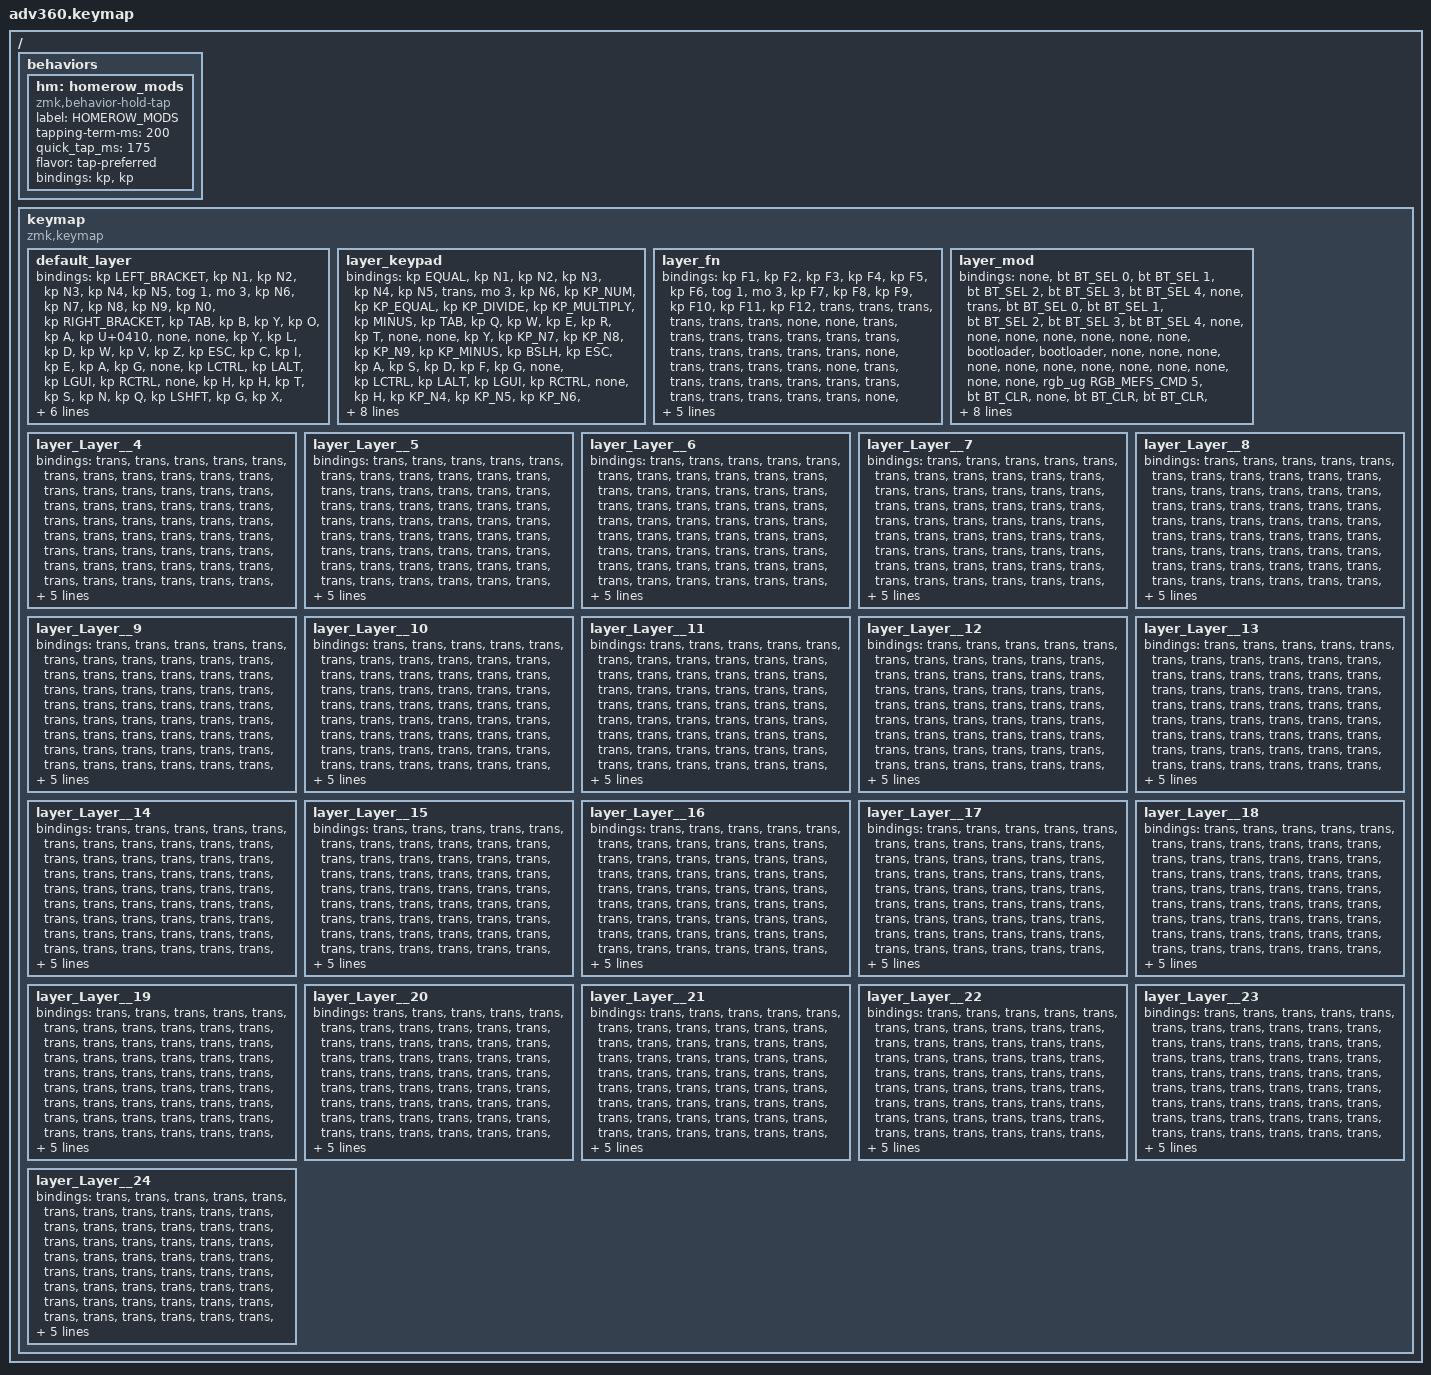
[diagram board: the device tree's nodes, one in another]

/*
 * Copyright (c) 2020 The ZMK Contributors
 *
 * SPDX-License-Identifier: MIT
 */


/* THIS FILE WAS GENERATED!
 *
 * This file was generated automatically. You may or may not want to
 * edit it directly.
 */

#include <behaviors.dtsi>
#include <dt-bindings/zmk/keys.h>
#include <dt-bindings/zmk/bt.h>
#include <dt-bindings/zmk/rgb.h>
#include <dt-bindings/zmk/backlight.h>

/ {
  behaviors {
    #include "macros.dtsi"
    #include "version.dtsi"

    hm: homerow_mods {
        compatible = "zmk,behavior-hold-tap";
        label = "HOMEROW_MODS";
        #binding-cells = <2>;
        tapping-term-ms = <200>;
        quick_tap_ms = <175>;
        flavor = "tap-preferred";
        bindings = <&kp>, <&kp>;
    };
  };

    keymap {
        compatible = "zmk,keymap";


        default_layer {
            bindings = <
 &kp LEFT_BRACKET     &kp N1    &kp N2    &kp N3     &kp N4      &kp N5             &tog 1      &mo 3     &kp N6     &kp N7     &kp N8     &kp N9     &kp N0  &kp RIGHT_BRACKET
          &kp TAB      &kp B     &kp Y     &kp O      &kp A  &kp U+0410              &none      &none      &kp Y      &kp L      &kp D      &kp W      &kp V              &kp Z
          &kp ESC      &kp C     &kp I     &kp E      &kp A       &kp G              &none  &kp LCTRL   &kp LALT                         &kp LGUI  &kp RCTRL              &none        &kp H   &kp H   &kp T   &kp S   &kp N      &kp Q
        &kp LSHFT      &kp G     &kp X     &kp J      &kp K       &kp B              &none      &none   &kp HOME      &none      &none  &kp PG_UP      &none              &none        &kp N   &kp R   &kp M   &kp F   &kp P  &kp RSHFT
            &mo 2  &kp GRAVE  &kp CAPS  &kp LEFT  &kp RIGHT    &kp BSPC            &kp DEL    &kp END  &kp PG_DN  &kp ENTER  &kp SPACE     &kp UP   &kp DOWN           &kp HASH  &kp AT_SIGN   &mo 2
            >;
        };

        layer_keypad {
            bindings = <
 &kp EQUAL     &kp N1    &kp N2    &kp N3     &kp N4    &kp N5             &trans      &mo 3     &kp N6  &kp KP_NUM  &kp KP_EQUAL  &kp KP_DIVIDE  &kp KP_MULTIPLY   &kp MINUS
   &kp TAB      &kp Q     &kp W     &kp E      &kp R     &kp T              &none      &none      &kp Y   &kp KP_N7     &kp KP_N8      &kp KP_N9     &kp KP_MINUS    &kp BSLH
   &kp ESC      &kp A     &kp S     &kp D      &kp F     &kp G              &none  &kp LCTRL   &kp LALT                                 &kp LGUI        &kp RCTRL       &none     &kp H  &kp KP_N4  &kp KP_N5  &kp KP_N6   &kp KP_PLUS    &kp SQT
 &kp LSHFT      &kp Z     &kp X     &kp C      &kp V     &kp B              &none      &none   &kp HOME       &none         &none      &kp PG_UP            &none       &none     &kp N  &kp KP_N1  &kp KP_N2  &kp KP_N3  &kp KP_ENTER  &kp RSHFT
     &mo 2  &kp GRAVE  &kp CAPS  &kp LEFT  &kp RIGHT  &kp BSPC            &kp DEL    &kp END  &kp PG_DN   &kp ENTER     &kp KP_N0         &kp UP         &kp DOWN  &kp KP_DOT  &kp RBKT      &mo 2
            >;
        };

        layer_fn {
            bindings = <
 &kp F1  &kp F2  &kp F3  &kp F4  &kp F5  &kp F6            &tog 1   &mo 3  &kp F7  &kp F8  &kp F9  &kp F10  &kp F11  &kp F12
 &trans  &trans  &trans  &trans  &trans  &trans             &none   &none  &trans  &trans  &trans   &trans   &trans   &trans
 &trans  &trans  &trans  &trans  &trans  &trans             &none  &trans  &trans                   &trans   &trans    &none  &trans  &trans  &trans  &trans  &trans  &trans
 &trans  &trans  &trans  &trans  &trans  &trans             &none   &none  &trans   &none   &none   &trans    &none    &none  &trans  &trans  &trans  &trans  &trans  &trans
 &trans  &trans  &trans  &trans  &trans  &trans            &trans  &trans  &trans  &trans  &trans   &trans   &trans   &trans  &trans  &trans
            >;
        };

        layer_mod {
            bindings = <
  &none  &bt BT_SEL 0  &bt BT_SEL 1  &bt BT_SEL 2  &bt BT_SEL 3     &bt BT_SEL 4                             &none       &trans  &bt BT_SEL 0  &bt BT_SEL 1     &bt BT_SEL 2  &bt BT_SEL 3  &bt BT_SEL 4                   &none
  &none         &none         &none         &none         &none            &none                       &bootloader  &bootloader         &none         &none            &none         &none         &none                   &none
  &none         &none         &none         &none         &none            &none            &rgb_ug RGB_MEFS_CMD 5   &bt BT_CLR         &none                                   &bt BT_CLR    &bt BT_CLR  &rgb_ug RGB_MEFS_CMD 5   &none   &none   &none   &none   &none   &none
  &none         &none         &none         &none         &none            &none                             &none        &none         &none         &none            &none         &none         &none                   &none   &none   &none   &none   &none   &none   &none
  &none         &none         &none    &bl BL_INC    &bl BL_DEC  &rgb_ug RGB_TOG                        &bl BL_TOG        &none         &none    &bl BL_TOG  &rgb_ug RGB_TOG    &bl BL_INC    &bl BL_DEC                   &none   &none   &none
            >;
        };

        layer_Layer__4 {
            bindings = <
 &trans  &trans  &trans  &trans  &trans  &trans            &trans  &trans  &trans  &trans  &trans  &trans  &trans  &trans
 &trans  &trans  &trans  &trans  &trans  &trans            &trans  &trans  &trans  &trans  &trans  &trans  &trans  &trans
 &trans  &trans  &trans  &trans  &trans  &trans            &trans  &trans  &trans                  &trans  &trans  &trans  &trans  &trans  &trans  &trans  &trans  &trans
 &trans  &trans  &trans  &trans  &trans  &trans            &trans  &trans  &trans  &trans  &trans  &trans  &trans  &trans  &trans  &trans  &trans  &trans  &trans  &trans
 &trans  &trans  &trans  &trans  &trans  &trans            &trans  &trans  &trans  &trans  &trans  &trans  &trans  &trans  &trans  &trans
            >;
        };

        layer_Layer__5 {
            bindings = <
 &trans  &trans  &trans  &trans  &trans  &trans            &trans  &trans  &trans  &trans  &trans  &trans  &trans  &trans
 &trans  &trans  &trans  &trans  &trans  &trans            &trans  &trans  &trans  &trans  &trans  &trans  &trans  &trans
 &trans  &trans  &trans  &trans  &trans  &trans            &trans  &trans  &trans                  &trans  &trans  &trans  &trans  &trans  &trans  &trans  &trans  &trans
 &trans  &trans  &trans  &trans  &trans  &trans            &trans  &trans  &trans  &trans  &trans  &trans  &trans  &trans  &trans  &trans  &trans  &trans  &trans  &trans
 &trans  &trans  &trans  &trans  &trans  &trans            &trans  &trans  &trans  &trans  &trans  &trans  &trans  &trans  &trans  &trans
            >;
        };

        layer_Layer__6 {
            bindings = <
 &trans  &trans  &trans  &trans  &trans  &trans            &trans  &trans  &trans  &trans  &trans  &trans  &trans  &trans
 &trans  &trans  &trans  &trans  &trans  &trans            &trans  &trans  &trans  &trans  &trans  &trans  &trans  &trans
 &trans  &trans  &trans  &trans  &trans  &trans            &trans  &trans  &trans                  &trans  &trans  &trans  &trans  &trans  &trans  &trans  &trans  &trans
 &trans  &trans  &trans  &trans  &trans  &trans            &trans  &trans  &trans  &trans  &trans  &trans  &trans  &trans  &trans  &trans  &trans  &trans  &trans  &trans
 &trans  &trans  &trans  &trans  &trans  &trans            &trans  &trans  &trans  &trans  &trans  &trans  &trans  &trans  &trans  &trans
            >;
        };

        layer_Layer__7 {
            bindings = <
 &trans  &trans  &trans  &trans  &trans  &trans            &trans  &trans  &trans  &trans  &trans  &trans  &trans  &trans
 &trans  &trans  &trans  &trans  &trans  &trans            &trans  &trans  &trans  &trans  &trans  &trans  &trans  &trans
 &trans  &trans  &trans  &trans  &trans  &trans            &trans  &trans  &trans                  &trans  &trans  &trans  &trans  &trans  &trans  &trans  &trans  &trans
 &trans  &trans  &trans  &trans  &trans  &trans            &trans  &trans  &trans  &trans  &trans  &trans  &trans  &trans  &trans  &trans  &trans  &trans  &trans  &trans
 &trans  &trans  &trans  &trans  &trans  &trans            &trans  &trans  &trans  &trans  &trans  &trans  &trans  &trans  &trans  &trans
            >;
        };

        layer_Layer__8 {
            bindings = <
 &trans  &trans  &trans  &trans  &trans  &trans            &trans  &trans  &trans  &trans  &trans  &trans  &trans  &trans
 &trans  &trans  &trans  &trans  &trans  &trans            &trans  &trans  &trans  &trans  &trans  &trans  &trans  &trans
 &trans  &trans  &trans  &trans  &trans  &trans            &trans  &trans  &trans                  &trans  &trans  &trans  &trans  &trans  &trans  &trans  &trans  &trans
 &trans  &trans  &trans  &trans  &trans  &trans            &trans  &trans  &trans  &trans  &trans  &trans  &trans  &trans  &trans  &trans  &trans  &trans  &trans  &trans
 &trans  &trans  &trans  &trans  &trans  &trans            &trans  &trans  &trans  &trans  &trans  &trans  &trans  &trans  &trans  &trans
            >;
        };

        layer_Layer__9 {
            bindings = <
 &trans  &trans  &trans  &trans  &trans  &trans            &trans  &trans  &trans  &trans  &trans  &trans  &trans  &trans
 &trans  &trans  &trans  &trans  &trans  &trans            &trans  &trans  &trans  &trans  &trans  &trans  &trans  &trans
 &trans  &trans  &trans  &trans  &trans  &trans            &trans  &trans  &trans                  &trans  &trans  &trans  &trans  &trans  &trans  &trans  &trans  &trans
 &trans  &trans  &trans  &trans  &trans  &trans            &trans  &trans  &trans  &trans  &trans  &trans  &trans  &trans  &trans  &trans  &trans  &trans  &trans  &trans
 &trans  &trans  &trans  &trans  &trans  &trans            &trans  &trans  &trans  &trans  &trans  &trans  &trans  &trans  &trans  &trans
            >;
        };

        layer_Layer__10 {
            bindings = <
 &trans  &trans  &trans  &trans  &trans  &trans            &trans  &trans  &trans  &trans  &trans  &trans  &trans  &trans
 &trans  &trans  &trans  &trans  &trans  &trans            &trans  &trans  &trans  &trans  &trans  &trans  &trans  &trans
 &trans  &trans  &trans  &trans  &trans  &trans            &trans  &trans  &trans                  &trans  &trans  &trans  &trans  &trans  &trans  &trans  &trans  &trans
 &trans  &trans  &trans  &trans  &trans  &trans            &trans  &trans  &trans  &trans  &trans  &trans  &trans  &trans  &trans  &trans  &trans  &trans  &trans  &trans
 &trans  &trans  &trans  &trans  &trans  &trans            &trans  &trans  &trans  &trans  &trans  &trans  &trans  &trans  &trans  &trans
            >;
        };

        layer_Layer__11 {
            bindings = <
 &trans  &trans  &trans  &trans  &trans  &trans            &trans  &trans  &trans  &trans  &trans  &trans  &trans  &trans
 &trans  &trans  &trans  &trans  &trans  &trans            &trans  &trans  &trans  &trans  &trans  &trans  &trans  &trans
 &trans  &trans  &trans  &trans  &trans  &trans            &trans  &trans  &trans                  &trans  &trans  &trans  &trans  &trans  &trans  &trans  &trans  &trans
 &trans  &trans  &trans  &trans  &trans  &trans            &trans  &trans  &trans  &trans  &trans  &trans  &trans  &trans  &trans  &trans  &trans  &trans  &trans  &trans
 &trans  &trans  &trans  &trans  &trans  &trans            &trans  &trans  &trans  &trans  &trans  &trans  &trans  &trans  &trans  &trans
            >;
        };

        layer_Layer__12 {
            bindings = <
 &trans  &trans  &trans  &trans  &trans  &trans            &trans  &trans  &trans  &trans  &trans  &trans  &trans  &trans
 &trans  &trans  &trans  &trans  &trans  &trans            &trans  &trans  &trans  &trans  &trans  &trans  &trans  &trans
 &trans  &trans  &trans  &trans  &trans  &trans            &trans  &trans  &trans                  &trans  &trans  &trans  &trans  &trans  &trans  &trans  &trans  &trans
 &trans  &trans  &trans  &trans  &trans  &trans            &trans  &trans  &trans  &trans  &trans  &trans  &trans  &trans  &trans  &trans  &trans  &trans  &trans  &trans
 &trans  &trans  &trans  &trans  &trans  &trans            &trans  &trans  &trans  &trans  &trans  &trans  &trans  &trans  &trans  &trans
            >;
        };

        layer_Layer__13 {
            bindings = <
 &trans  &trans  &trans  &trans  &trans  &trans            &trans  &trans  &trans  &trans  &trans  &trans  &trans  &trans
 &trans  &trans  &trans  &trans  &trans  &trans            &trans  &trans  &trans  &trans  &trans  &trans  &trans  &trans
 &trans  &trans  &trans  &trans  &trans  &trans            &trans  &trans  &trans                  &trans  &trans  &trans  &trans  &trans  &trans  &trans  &trans  &trans
 &trans  &trans  &trans  &trans  &trans  &trans            &trans  &trans  &trans  &trans  &trans  &trans  &trans  &trans  &trans  &trans  &trans  &trans  &trans  &trans
 &trans  &trans  &trans  &trans  &trans  &trans            &trans  &trans  &trans  &trans  &trans  &trans  &trans  &trans  &trans  &trans
            >;
        };

        layer_Layer__14 {
            bindings = <
 &trans  &trans  &trans  &trans  &trans  &trans            &trans  &trans  &trans  &trans  &trans  &trans  &trans  &trans
 &trans  &trans  &trans  &trans  &trans  &trans            &trans  &trans  &trans  &trans  &trans  &trans  &trans  &trans
 &trans  &trans  &trans  &trans  &trans  &trans            &trans  &trans  &trans                  &trans  &trans  &trans  &trans  &trans  &trans  &trans  &trans  &trans
 &trans  &trans  &trans  &trans  &trans  &trans            &trans  &trans  &trans  &trans  &trans  &trans  &trans  &trans  &trans  &trans  &trans  &trans  &trans  &trans
 &trans  &trans  &trans  &trans  &trans  &trans            &trans  &trans  &trans  &trans  &trans  &trans  &trans  &trans  &trans  &trans
            >;
        };

        layer_Layer__15 {
            bindings = <
 &trans  &trans  &trans  &trans  &trans  &trans            &trans  &trans  &trans  &trans  &trans  &trans  &trans  &trans
 &trans  &trans  &trans  &trans  &trans  &trans            &trans  &trans  &trans  &trans  &trans  &trans  &trans  &trans
 &trans  &trans  &trans  &trans  &trans  &trans            &trans  &trans  &trans                  &trans  &trans  &trans  &trans  &trans  &trans  &trans  &trans  &trans
 &trans  &trans  &trans  &trans  &trans  &trans            &trans  &trans  &trans  &trans  &trans  &trans  &trans  &trans  &trans  &trans  &trans  &trans  &trans  &trans
 &trans  &trans  &trans  &trans  &trans  &trans            &trans  &trans  &trans  &trans  &trans  &trans  &trans  &trans  &trans  &trans
            >;
        };

        layer_Layer__16 {
            bindings = <
 &trans  &trans  &trans  &trans  &trans  &trans            &trans  &trans  &trans  &trans  &trans  &trans  &trans  &trans
 &trans  &trans  &trans  &trans  &trans  &trans            &trans  &trans  &trans  &trans  &trans  &trans  &trans  &trans
 &trans  &trans  &trans  &trans  &trans  &trans            &trans  &trans  &trans                  &trans  &trans  &trans  &trans  &trans  &trans  &trans  &trans  &trans
 &trans  &trans  &trans  &trans  &trans  &trans            &trans  &trans  &trans  &trans  &trans  &trans  &trans  &trans  &trans  &trans  &trans  &trans  &trans  &trans
 &trans  &trans  &trans  &trans  &trans  &trans            &trans  &trans  &trans  &trans  &trans  &trans  &trans  &trans  &trans  &trans
            >;
        };

        layer_Layer__17 {
            bindings = <
 &trans  &trans  &trans  &trans  &trans  &trans            &trans  &trans  &trans  &trans  &trans  &trans  &trans  &trans
 &trans  &trans  &trans  &trans  &trans  &trans            &trans  &trans  &trans  &trans  &trans  &trans  &trans  &trans
 &trans  &trans  &trans  &trans  &trans  &trans            &trans  &trans  &trans                  &trans  &trans  &trans  &trans  &trans  &trans  &trans  &trans  &trans
 &trans  &trans  &trans  &trans  &trans  &trans            &trans  &trans  &trans  &trans  &trans  &trans  &trans  &trans  &trans  &trans  &trans  &trans  &trans  &trans
 &trans  &trans  &trans  &trans  &trans  &trans            &trans  &trans  &trans  &trans  &trans  &trans  &trans  &trans  &trans  &trans
            >;
        };

        layer_Layer__18 {
            bindings = <
 &trans  &trans  &trans  &trans  &trans  &trans            &trans  &trans  &trans  &trans  &trans  &trans  &trans  &trans
 &trans  &trans  &trans  &trans  &trans  &trans            &trans  &trans  &trans  &trans  &trans  &trans  &trans  &trans
 &trans  &trans  &trans  &trans  &trans  &trans            &trans  &trans  &trans                  &trans  &trans  &trans  &trans  &trans  &trans  &trans  &trans  &trans
 &trans  &trans  &trans  &trans  &trans  &trans            &trans  &trans  &trans  &trans  &trans  &trans  &trans  &trans  &trans  &trans  &trans  &trans  &trans  &trans
 &trans  &trans  &trans  &trans  &trans  &trans            &trans  &trans  &trans  &trans  &trans  &trans  &trans  &trans  &trans  &trans
            >;
        };

        layer_Layer__19 {
            bindings = <
 &trans  &trans  &trans  &trans  &trans  &trans            &trans  &trans  &trans  &trans  &trans  &trans  &trans  &trans
 &trans  &trans  &trans  &trans  &trans  &trans            &trans  &trans  &trans  &trans  &trans  &trans  &trans  &trans
 &trans  &trans  &trans  &trans  &trans  &trans            &trans  &trans  &trans                  &trans  &trans  &trans  &trans  &trans  &trans  &trans  &trans  &trans
 &trans  &trans  &trans  &trans  &trans  &trans            &trans  &trans  &trans  &trans  &trans  &trans  &trans  &trans  &trans  &trans  &trans  &trans  &trans  &trans
 &trans  &trans  &trans  &trans  &trans  &trans            &trans  &trans  &trans  &trans  &trans  &trans  &trans  &trans  &trans  &trans
            >;
        };

        layer_Layer__20 {
            bindings = <
 &trans  &trans  &trans  &trans  &trans  &trans            &trans  &trans  &trans  &trans  &trans  &trans  &trans  &trans
 &trans  &trans  &trans  &trans  &trans  &trans            &trans  &trans  &trans  &trans  &trans  &trans  &trans  &trans
 &trans  &trans  &trans  &trans  &trans  &trans            &trans  &trans  &trans                  &trans  &trans  &trans  &trans  &trans  &trans  &trans  &trans  &trans
 &trans  &trans  &trans  &trans  &trans  &trans            &trans  &trans  &trans  &trans  &trans  &trans  &trans  &trans  &trans  &trans  &trans  &trans  &trans  &trans
 &trans  &trans  &trans  &trans  &trans  &trans            &trans  &trans  &trans  &trans  &trans  &trans  &trans  &trans  &trans  &trans
            >;
        };

        layer_Layer__21 {
            bindings = <
 &trans  &trans  &trans  &trans  &trans  &trans            &trans  &trans  &trans  &trans  &trans  &trans  &trans  &trans
 &trans  &trans  &trans  &trans  &trans  &trans            &trans  &trans  &trans  &trans  &trans  &trans  &trans  &trans
 &trans  &trans  &trans  &trans  &trans  &trans            &trans  &trans  &trans                  &trans  &trans  &trans  &trans  &trans  &trans  &trans  &trans  &trans
 &trans  &trans  &trans  &trans  &trans  &trans            &trans  &trans  &trans  &trans  &trans  &trans  &trans  &trans  &trans  &trans  &trans  &trans  &trans  &trans
 &trans  &trans  &trans  &trans  &trans  &trans            &trans  &trans  &trans  &trans  &trans  &trans  &trans  &trans  &trans  &trans
            >;
        };

        layer_Layer__22 {
            bindings = <
 &trans  &trans  &trans  &trans  &trans  &trans            &trans  &trans  &trans  &trans  &trans  &trans  &trans  &trans
 &trans  &trans  &trans  &trans  &trans  &trans            &trans  &trans  &trans  &trans  &trans  &trans  &trans  &trans
 &trans  &trans  &trans  &trans  &trans  &trans            &trans  &trans  &trans                  &trans  &trans  &trans  &trans  &trans  &trans  &trans  &trans  &trans
 &trans  &trans  &trans  &trans  &trans  &trans            &trans  &trans  &trans  &trans  &trans  &trans  &trans  &trans  &trans  &trans  &trans  &trans  &trans  &trans
 &trans  &trans  &trans  &trans  &trans  &trans            &trans  &trans  &trans  &trans  &trans  &trans  &trans  &trans  &trans  &trans
            >;
        };

        layer_Layer__23 {
            bindings = <
 &trans  &trans  &trans  &trans  &trans  &trans            &trans  &trans  &trans  &trans  &trans  &trans  &trans  &trans
 &trans  &trans  &trans  &trans  &trans  &trans            &trans  &trans  &trans  &trans  &trans  &trans  &trans  &trans
 &trans  &trans  &trans  &trans  &trans  &trans            &trans  &trans  &trans                  &trans  &trans  &trans  &trans  &trans  &trans  &trans  &trans  &trans
 &trans  &trans  &trans  &trans  &trans  &trans            &trans  &trans  &trans  &trans  &trans  &trans  &trans  &trans  &trans  &trans  &trans  &trans  &trans  &trans
 &trans  &trans  &trans  &trans  &trans  &trans            &trans  &trans  &trans  &trans  &trans  &trans  &trans  &trans  &trans  &trans
            >;
        };

        layer_Layer__24 {
            bindings = <
 &trans  &trans  &trans  &trans  &trans  &trans            &trans  &trans  &trans  &trans  &trans  &trans  &trans  &trans
 &trans  &trans  &trans  &trans  &trans  &trans            &trans  &trans  &trans  &trans  &trans  &trans  &trans  &trans
 &trans  &trans  &trans  &trans  &trans  &trans            &trans  &trans  &trans                  &trans  &trans  &trans  &trans  &trans  &trans  &trans  &trans  &trans
 &trans  &trans  &trans  &trans  &trans  &trans            &trans  &trans  &trans  &trans  &trans  &trans  &trans  &trans  &trans  &trans  &trans  &trans  &trans  &trans
 &trans  &trans  &trans  &trans  &trans  &trans            &trans  &trans  &trans  &trans  &trans  &trans  &trans  &trans  &trans  &trans
            >;
        };

    };
};
